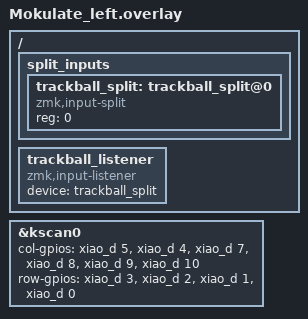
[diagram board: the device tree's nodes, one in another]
#include "Mokulate.dtsi"

&kscan0 {
    col-gpios
        = <&xiao_d 5 GPIO_ACTIVE_HIGH>   /* Col0 */
        , <&xiao_d 4 GPIO_ACTIVE_HIGH>   /* Col1 */
        , <&xiao_d 7 GPIO_ACTIVE_HIGH>   /* Col2 */
        , <&xiao_d 8 GPIO_ACTIVE_HIGH>   /* Col3 */
        , <&xiao_d 9 GPIO_ACTIVE_HIGH>   /* Col4 */
        , <&xiao_d 10 GPIO_ACTIVE_HIGH>  /* Col5 */
        ;
    row-gpios
        = <&xiao_d 3 (GPIO_ACTIVE_HIGH | GPIO_PULL_DOWN)>  /* Row0 */
        , <&xiao_d 2 (GPIO_ACTIVE_HIGH | GPIO_PULL_DOWN)>  /* Row1 */
        , <&xiao_d 1 (GPIO_ACTIVE_HIGH | GPIO_PULL_DOWN)>  /* Row2 */
        , <&xiao_d 0 (GPIO_ACTIVE_HIGH | GPIO_PULL_DOWN)>  /* Row3 */
        ;
};

// Split input configuration (central side - receives trackball data from peripheral)
/ {
    split_inputs {
        #address-cells = <1>;
        #size-cells = <0>;

        trackball_split: trackball_split@0 {
            compatible = "zmk,input-split";
            reg = <0>;
        };
    };

    trackball_listener: trackball_listener {
        compatible = "zmk,input-listener";
        device = <&trackball_split>;
        status = "okay";
    };
};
